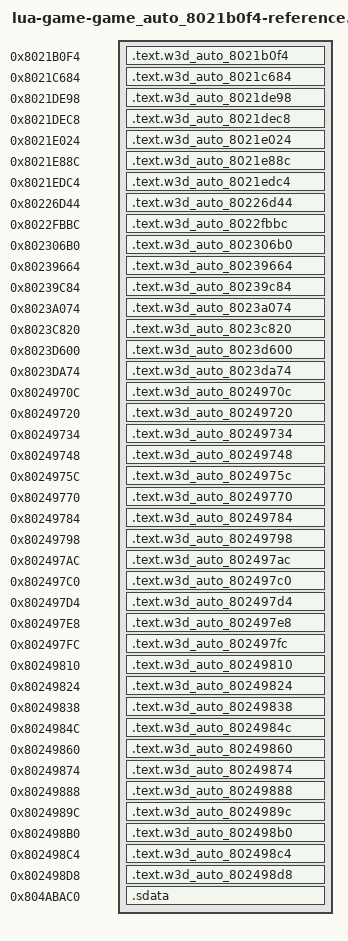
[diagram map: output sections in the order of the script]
/* Generated reference-only placements. All bodies are source-built. */
OUTPUT_FORMAT("elf32-powerpc")
OUTPUT_ARCH(powerpc)
ENTRY(w3d_auto_8021b0f4)
_SDA_BASE_ = 0x804b2540;
_SDA2_BASE_ = 0x804c2540;
fn_8006E71C = 0x8006e71c;
fn_80129878 = 0x80129878;
fn_8015CCBC = 0x8015ccbc;
fn_80162C18 = 0x80162c18;
fn_80165254 = 0x80165254;
fn_801E8D9C = 0x801e8d9c;
fn_801EF174 = 0x801ef174;
fn_801EF380 = 0x801ef380;
fn_8021B194 = 0x8021b194;
fn_8021B8C0 = 0x8021b8c0;
fn_8021BD4C = 0x8021bd4c;
fn_8021BF14 = 0x8021bf14;
fn_8021BF3C = 0x8021bf3c;
fn_8021C144 = 0x8021c144;
fn_8021C48C = 0x8021c48c;
fn_8021C684 = 0x8021c684;
fn_8021E248 = 0x8021e248;
SECTIONS {
  .text.w3d_auto_8021b0f4 0x8021b0f4 : { *(.text.w3d_auto_8021b0f4) }
  .text.w3d_auto_8021c684 0x8021c684 : { *(.text.w3d_auto_8021c684) }
  .text.w3d_auto_8021de98 0x8021de98 : { *(.text.w3d_auto_8021de98) }
  .text.w3d_auto_8021dec8 0x8021dec8 : { *(.text.w3d_auto_8021dec8) }
  .text.w3d_auto_8021e024 0x8021e024 : { *(.text.w3d_auto_8021e024) }
  .text.w3d_auto_8021e88c 0x8021e88c : { *(.text.w3d_auto_8021e88c) }
  .text.w3d_auto_8021edc4 0x8021edc4 : { *(.text.w3d_auto_8021edc4) }
  .text.w3d_auto_80226d44 0x80226d44 : { *(.text.w3d_auto_80226d44) }
  .text.w3d_auto_8022fbbc 0x8022fbbc : { *(.text.w3d_auto_8022fbbc) }
  .text.w3d_auto_802306b0 0x802306b0 : { *(.text.w3d_auto_802306b0) }
  .text.w3d_auto_80239664 0x80239664 : { *(.text.w3d_auto_80239664) }
  .text.w3d_auto_80239c84 0x80239c84 : { *(.text.w3d_auto_80239c84) }
  .text.w3d_auto_8023a074 0x8023a074 : { *(.text.w3d_auto_8023a074) }
  .text.w3d_auto_8023c820 0x8023c820 : { *(.text.w3d_auto_8023c820) }
  .text.w3d_auto_8023d600 0x8023d600 : { *(.text.w3d_auto_8023d600) }
  .text.w3d_auto_8023da74 0x8023da74 : { *(.text.w3d_auto_8023da74) }
  .text.w3d_auto_8024970c 0x8024970c : { *(.text.w3d_auto_8024970c) }
  .text.w3d_auto_80249720 0x80249720 : { *(.text.w3d_auto_80249720) }
  .text.w3d_auto_80249734 0x80249734 : { *(.text.w3d_auto_80249734) }
  .text.w3d_auto_80249748 0x80249748 : { *(.text.w3d_auto_80249748) }
  .text.w3d_auto_8024975c 0x8024975c : { *(.text.w3d_auto_8024975c) }
  .text.w3d_auto_80249770 0x80249770 : { *(.text.w3d_auto_80249770) }
  .text.w3d_auto_80249784 0x80249784 : { *(.text.w3d_auto_80249784) }
  .text.w3d_auto_80249798 0x80249798 : { *(.text.w3d_auto_80249798) }
  .text.w3d_auto_802497ac 0x802497ac : { *(.text.w3d_auto_802497ac) }
  .text.w3d_auto_802497c0 0x802497c0 : { *(.text.w3d_auto_802497c0) }
  .text.w3d_auto_802497d4 0x802497d4 : { *(.text.w3d_auto_802497d4) }
  .text.w3d_auto_802497e8 0x802497e8 : { *(.text.w3d_auto_802497e8) }
  .text.w3d_auto_802497fc 0x802497fc : { *(.text.w3d_auto_802497fc) }
  .text.w3d_auto_80249810 0x80249810 : { *(.text.w3d_auto_80249810) }
  .text.w3d_auto_80249824 0x80249824 : { *(.text.w3d_auto_80249824) }
  .text.w3d_auto_80249838 0x80249838 : { *(.text.w3d_auto_80249838) }
  .text.w3d_auto_8024984c 0x8024984c : { *(.text.w3d_auto_8024984c) }
  .text.w3d_auto_80249860 0x80249860 : { *(.text.w3d_auto_80249860) }
  .text.w3d_auto_80249874 0x80249874 : { *(.text.w3d_auto_80249874) }
  .text.w3d_auto_80249888 0x80249888 : { *(.text.w3d_auto_80249888) }
  .text.w3d_auto_8024989c 0x8024989c : { *(.text.w3d_auto_8024989c) }
  .text.w3d_auto_802498b0 0x802498b0 : { *(.text.w3d_auto_802498b0) }
  .text.w3d_auto_802498c4 0x802498c4 : { *(.text.w3d_auto_802498c4) }
  .text.w3d_auto_802498d8 0x802498d8 : { *(.text.w3d_auto_802498d8) }
  .sdata 0x804abac0 (NOLOAD) : {
    . = 0x0; lbl_804ABAC0 = .;
    . = 0x5cc8; lbl_804B1788 = .;
    . += 1; }
  /DISCARD/ : { *(.text*) *(.rodata*) *(.data*) *(.bss*) *(.sdata*) *(.sbss*) *(.comment) }
}
